# M440 register map
File version: 0.1
Registers are 32-bit, read-write, reset 0x0 unless marked. A register's access mark holds for its fields unless they carry their own. Offsets are from the block's base; [hi:lo] are bit positions; {n}, {i} and the like mark numbered series.

## DAA — 10bit D_A Converter
Base 0x44054000
Same registers: DAB 0x44055000
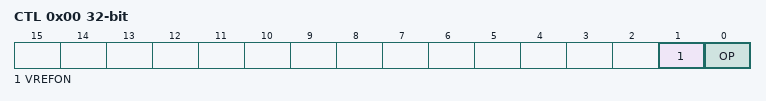
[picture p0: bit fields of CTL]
0x00 CTL — Control Register
  [1] VREFON, [0] OP
0x04 REG — Output Register
  [9:0] DAC

## TD — Timer D-common
Base 0x40058000
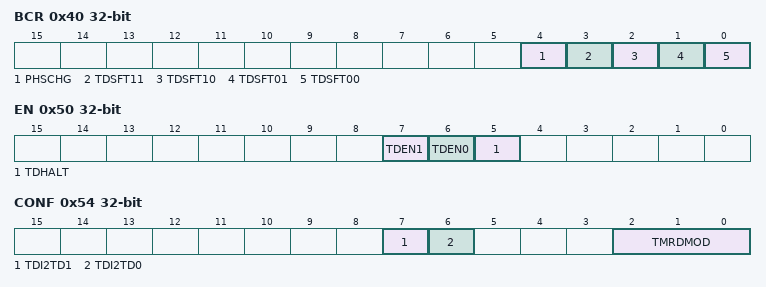
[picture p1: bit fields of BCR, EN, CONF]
0x40 BCR — Update Flag Setting Register
  [4] PHSCHG, [3] TDSFT11, [2] TDSFT10, [1] TDSFT01, [0] TDSFT00
0x50 EN — Timer Enable Register
  [7] TDEN1, [6] TDEN0, [5] TDHALT
0x54 CONF — Timer Configuration Register
  [7] TDI2TD1, [6] TDI2TD0, [2:0] TMRDMOD

## TD0 — Timer D-unit0
Base 0x40058000
0x00 RUN — Timer Run Register (unit0)
  [0] TDRUN wo
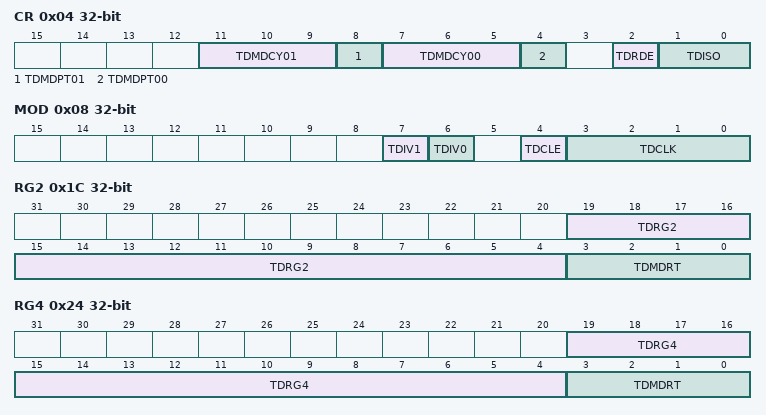
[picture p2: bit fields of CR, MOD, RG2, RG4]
0x04 CR — Timer Control Register (unit0)
  [11:9] TDMDCY01, [8] TDMDPT01, [7:5] TDMDCY00, [4] TDMDPT00, [2] TDRDE, [1:0] TDISO
0x08 MOD — Timer Mode Register (unit0)
  [7] TDIV1, [6] TDIV0, [4] TDCLE, [3:0] TDCLK
0x0C DMA — DMA Request Enable Register (unit0)
  [0] DMAEN
0x14 RG0 — Timer Register0 (unit0)
  [15:0] TDRG0
0x18 RG1 — Timer Register1 (unit0)
  [15:0] TDRG1
0x1C RG2 — Timer Register2 (unit0)
  [19:4] TDRG2, [3:0] TDMDRT
0x20 RG3 — Timer Register3 (unit0)
  [15:0] TDRG3
0x24 RG4 — Timer Register4 (unit0)
  [19:4] TDRG4, [3:0] TDMDRT
0x28 RG5 — Timer Register5 (unit0)
  [15:0] TDRG5
0x114 CP0 ro — Compare Register0 (unit0)
  [15:0] CPRG0
0x118 CP1 ro — Compare Register1 (unit0)
  [15:0] CPRG1
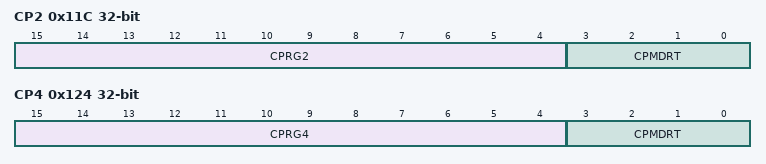
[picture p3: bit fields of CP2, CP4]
0x11C CP2 ro — Compare Register2 (unit0)
  [15:4] CPRG2, [3:0] CPMDRT
0x120 CP3 ro — Compare Register3 (unit0)
  [15:0] CPRG3
0x124 CP4 — Compare Register4 (unit0)
  [15:4] CPRG4 ro, [3:0] CPMDRT ro
0x128 CP5 ro — Compare Register5 (unit0)
  [15:0] CPRG5

## TD1 — Timer D-unit1
Base 0x40058000
0x2C RG0 — Timer Register0 (unit1)
  [15:0] TDRG0
0x30 RG1 — Timer Register1 (unit1)
  [15:0] TDRG1
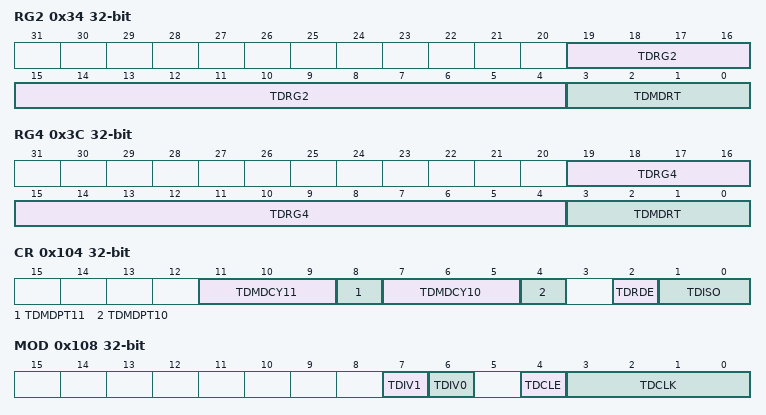
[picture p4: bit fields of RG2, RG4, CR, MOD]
0x34 RG2 — Timer Register2 (unit1)
  [19:4] TDRG2, [3:0] TDMDRT
0x38 RG3 — Timer Register3 (unit1)
  [15:0] TDRG3
0x3C RG4 — Timer Register4 (unit1)
  [19:4] TDRG4, [3:0] TDMDRT
0x100 RUN — Timer Run Register (unit1)
  [0] TDRUN wo
0x104 CR — Timer Control Register (unit1)
  [11:9] TDMDCY11, [8] TDMDPT11, [7:5] TDMDCY10, [4] TDMDPT10, [2] TDRDE, [1:0] TDISO
0x108 MOD — Timer Mode Register (unit1)
  [7] TDIV1, [6] TDIV0, [4] TDCLE, [3:0] TDCLK
0x10C DMA — DMA Request Enable Register (unit1)
  [0] DMAEN
0x12C CP0 ro — Compare Register0 (unit1)
  [15:0] CPRG0
0x130 CP1 ro — Compare Register1 (unit1)
  [15:0] CPRG1
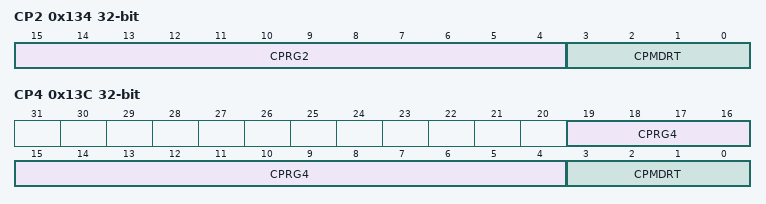
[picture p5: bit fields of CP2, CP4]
0x134 CP2 ro — Compare Register2 (unit1)
  [15:4] CPRG2, [3:0] CPMDRT
0x138 CP3 ro — Compare Register3 (unit1)
  [15:0] CPRG3
0x13C CP4 — Compare Register4 (unit1)
  [19:4] CPRG4 ro, [3:0] CPMDRT ro

## EXB — External Bus Interface(EXB)
Base 0x4405C000
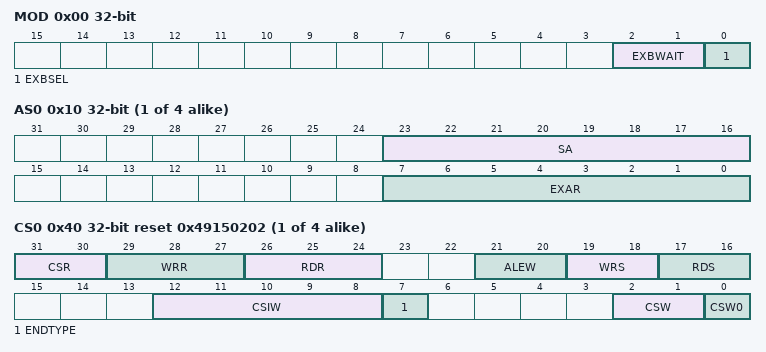
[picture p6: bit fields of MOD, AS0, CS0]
0x00 MOD — External Bus Mode Register
  [2:1] EXBWAIT, [0] EXBSEL
{0x10+4i} AS{i} (i=0..3) — External Bus Base Address and CS Space setting Register {i}
  [23:16] SA, [7:0] EXAR
{0x40+4i} CS{i} reset 0x49150202 (i=0..3) — Chip Select and Wait Controller Register {i}
  [31:30] CSR, [29:27] WRR, [26:24] RDR, [21:20] ALEW, [19:18] WRS, [17:16] RDS, [12:8] CSIW, [7] ENDTYPE, [2:1] CSW, [0] CSW0

## EPHC — Enhannced Two Aspect Pulse Input Counter (Enhannced 2-Phase Pulse Input Timer) (EPHC) for CPU
Base 0x44060000
0x00 EN — EPHC Enable Register
  [0] EN
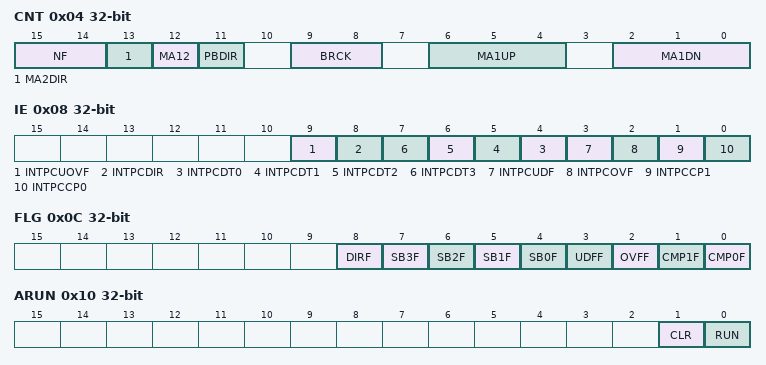
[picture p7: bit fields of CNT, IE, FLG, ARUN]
0x04 CNT — EPHC Control Register
  [15:14] NF, [13] MA2DIR, [12] MA12, [11] PBDIR, [9:8] BRCK, [6:4] MA1UP, [2:0] MA1DN
0x08 IE — EPHC Interrupt Enable Register
  [9] INTPCUOVF, [8] INTPCDIR, [n+4] INTPCDT{n} (n=0..3), [3] INTPCUDF, [2] INTPCOVF, [1] INTPCCP1, [0] INTPCCP0
0x0C FLG — EPHC Status Register
  [8] DIRF, [n+4] SB{n}F (n=0..3), [3] UDFF, [2] OVFF, [1] CMP1F, [0] CMP0F
0x10 ARUN — EPHC 16-bit Counter Run Register
  [1] CLR, [0] RUN
0x14 ACP0 — EPHC Pulse Counter Compare 0 Register
  [15:0] CMP0
0x18 ACP1 — EPHC Pulse Counter Compare 1 Register
  [15:0] CMP1
0x1C ADAT reset 0x7FFF — EPHC 16-bit Counter Read Register
  [15:0] DAT
0x20 BRUN — EPHC 24-bit Counter Run Register
  [0] T24RUN
0x24 BDMA — EPHC DMAE Request Enable Register
  [3:0] DMADT
0x28 BUC ro — EPHC 24-bit Counter Read Register
  [23:0] T24UCR
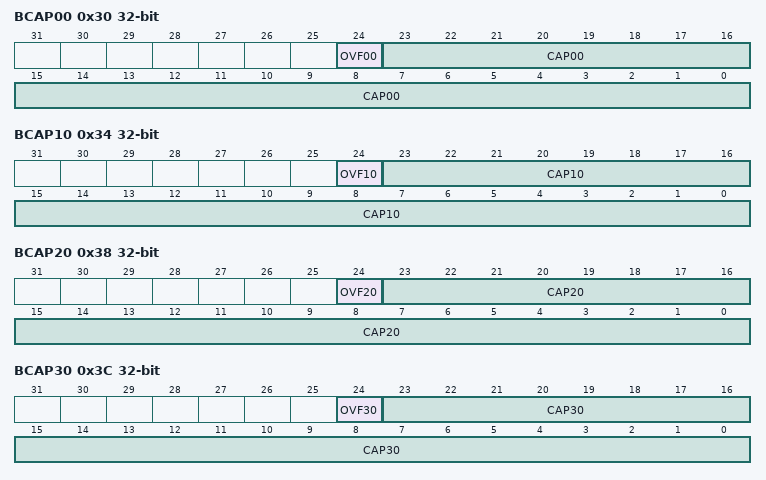
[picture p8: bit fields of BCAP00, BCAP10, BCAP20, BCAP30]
0x30 BCAP00 ro — EPHC Capture 00 Register
  [24] OVF00, [23:0] CAP00
0x34 BCAP10 ro — EPHC Capture 10 Register
  [24] OVF10, [23:0] CAP10
0x38 BCAP20 ro — EPHC Capture 20 Register
  [24] OVF20, [23:0] CAP20
0x3C BCAP30 ro — EPHC Capture 30 Register
  [24] OVF30, [23:0] CAP30
{0x40+4i} B{i}DAT ro (i=0..3) — EPHC Cycle {i} Register
  [23:0] B{i}DAT
0x50 BCDAT ro — EPHC Cycle Common Register
  [23:0] BCDAT
{0x60+4i} B{i}PDT ro (i=0..3) — EPHC Phase DifferEPHCe {i} Register
  [23:0] B{i}PDT
